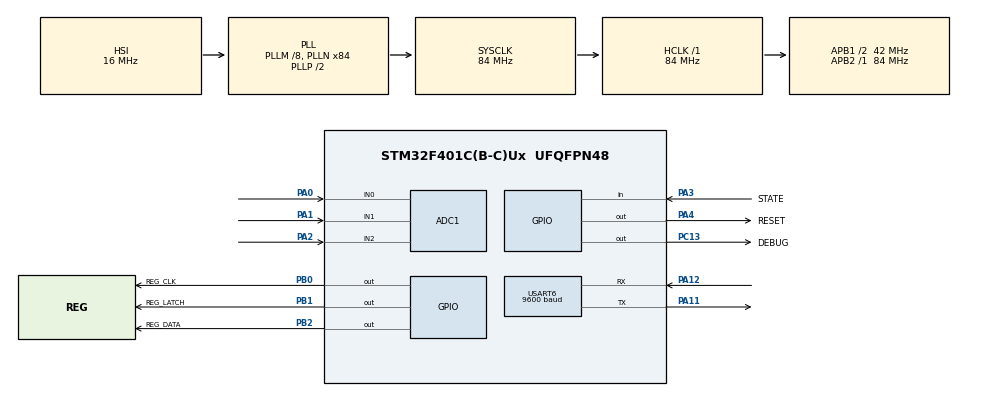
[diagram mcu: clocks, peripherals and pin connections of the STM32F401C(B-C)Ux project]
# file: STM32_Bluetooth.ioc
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ADC1.Channel-0\#ChannelRegularConversion=ADC_CHANNEL_0
ADC1.Channel-1\#ChannelRegularConversion=ADC_CHANNEL_1
ADC1.Channel-2\#ChannelRegularConversion=ADC_CHANNEL_2
ADC1.ContinuousConvMode=ENABLE
ADC1.NbrOfConversion=3
ADC1.NbrOfConversionFlag=1
ADC1.Rank-0\#ChannelRegularConversion=1
ADC1.Rank-1\#ChannelRegularConversion=2
ADC1.Rank-2\#ChannelRegularConversion=3
ADC1.SamplingTime-0\#ChannelRegularConversion=ADC_SAMPLETIME_56CYCLES
ADC1.SamplingTime-1\#ChannelRegularConversion=ADC_SAMPLETIME_56CYCLES
ADC1.SamplingTime-2\#ChannelRegularConversion=ADC_SAMPLETIME_56CYCLES
ADC1.master=1
Mcu.Family=STM32F4
Mcu.Name=STM32F401C(B-C)Ux
Mcu.Package=UFQFPN48
NVIC.PriorityGroup=NVIC_PRIORITYGROUP_4
NVIC.USART6_IRQn=true\:0\:0\:false\:false\:true\:true\:true\:true
PA0-WKUP.Signal=ADCx_IN0
PA1.Signal=ADCx_IN1
PA11.Mode=Asynchronous
PA11.Signal=USART6_TX
PA12.Mode=Asynchronous
PA12.Signal=USART6_RX
PA2.Signal=ADCx_IN2
PA3.GPIO_Label=STATE
PA3.GPIO_PuPd=GPIO_PULLDOWN
PA3.Signal=GPIO_Input
PA4.GPIO_Label=RESET
PA4.PinState=GPIO_PIN_SET
PA4.Signal=GPIO_Output
PB0.GPIO_Label=REG_CLK
PB0.GPIO_Speed=GPIO_SPEED_FREQ_VERY_HIGH
PB0.PinState=GPIO_PIN_RESET
PB0.Signal=GPIO_Output
PB1.GPIO_Label=REG_LATCH
PB1.GPIO_Speed=GPIO_SPEED_FREQ_VERY_HIGH
PB1.PinState=GPIO_PIN_RESET
PB1.Signal=GPIO_Output
PB2.GPIO_Label=REG_DATA
PB2.GPIO_Speed=GPIO_SPEED_FREQ_VERY_HIGH
PB2.PinState=GPIO_PIN_RESET
PB2.Signal=GPIO_Output
PC13-ANTI_TAMP.GPIO_Label=DEBUG
PC13-ANTI_TAMP.Signal=GPIO_Output
PH0\ -\ OSC_IN.Mode=HSE-External-Oscillator
PH0\ -\ OSC_IN.Signal=RCC_OSC_IN
PH1\ -\ OSC_OUT.Mode=HSE-External-Oscillator
PH1\ -\ OSC_OUT.Signal=RCC_OSC_OUT
ProjectManager.HeapSize=0x200
ProjectManager.StackSize=0x400
ProjectManager.TargetToolchain=STM32CubeIDE
RCC.48MHZClocksFreq_Value=42000000
RCC.AHBFreq_Value=84000000
RCC.APB1CLKDivider=RCC_HCLK_DIV2
RCC.APB1Freq_Value=42000000
RCC.APB1TimFreq_Value=84000000
RCC.APB2Freq_Value=84000000
RCC.APB2TimFreq_Value=84000000
RCC.CortexFreq_Value=84000000
RCC.HCLKFreq_Value=84000000
RCC.HSE_VALUE=25000000
RCC.HSI_VALUE=16000000
RCC.LSE_VALUE=32768
RCC.PLLM=8
RCC.PLLN=84
RCC.SYSCLKFreq_VALUE=84000000
RCC.SYSCLKSource=RCC_SYSCLKSOURCE_PLLCLK
RCC.VCOOutputFreq_Value=168000000
SH.ADCx_IN0.0=ADC1_IN0,IN0
SH.ADCx_IN1.0=ADC1_IN1,IN1
SH.ADCx_IN2.0=ADC1_IN2,IN2
USART6.BaudRate=9600
USART6.VirtualMode=VM_ASYNC
board=custom

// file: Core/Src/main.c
/* USER CODE BEGIN Header */
/**
  ******************************************************************************
  * @file           : main.c
  * @brief          : Main program body
  ******************************************************************************
  * @attention
  *
  * Copyright (c) 2024 STMicroelectronics.
  * All rights reserved.
  *
  * This software is licensed under terms that can be found in the LICENSE file
  * in the root directory of this software component.
  * If no LICENSE file comes with this software, it is provided AS-IS.
  *
  ******************************************************************************
  */
/* USER CODE END Header */
#include "main.h"

/* USER CODE BEGIN Includes */
#include "my_main.h"
/* USER CODE END Includes */

ADC_HandleTypeDef hadc1;

UART_HandleTypeDef huart6;

void SystemClock_Config(void);
static void MX_GPIO_Init(void);
static void MX_ADC1_Init(void);
static void MX_USART6_UART_Init(void);

int main(void)
{

  /* MCU Configuration--------------------------------------------------------*/

  /* Reset of all peripherals, Initializes the Flash interface and the Systick. */
  HAL_Init();

  /* Configure the system clock */
  SystemClock_Config();

  /* Initialize all configured peripherals */
  MX_GPIO_Init();
  MX_ADC1_Init();
  MX_USART6_UART_Init();

  /* Infinite loop */
  while (1)
  {

    /* USER CODE BEGIN 3 */
	  MAIN();
  }
  /* USER CODE END 3 */
}

void SystemClock_Config(void)
{
  RCC_OscInitTypeDef RCC_OscInitStruct = {0};
  RCC_ClkInitTypeDef RCC_ClkInitStruct = {0};

  /** Configure the main internal regulator output voltage
  */
  __HAL_RCC_PWR_CLK_ENABLE();
  __HAL_PWR_VOLTAGESCALING_CONFIG(PWR_REGULATOR_VOLTAGE_SCALE2);

  /** Initializes the RCC Oscillators according to the specified parameters
  * in the RCC_OscInitTypeDef structure.
  */
  RCC_OscInitStruct.OscillatorType = RCC_OSCILLATORTYPE_HSI;
  RCC_OscInitStruct.HSIState = RCC_HSI_ON;
  RCC_OscInitStruct.HSICalibrationValue = RCC_HSICALIBRATION_DEFAULT;
  RCC_OscInitStruct.PLL.PLLState = RCC_PLL_ON;
  RCC_OscInitStruct.PLL.PLLSource = RCC_PLLSOURCE_HSI;
  RCC_OscInitStruct.PLL.PLLM = 8;
  RCC_OscInitStruct.PLL.PLLN = 84;
  RCC_OscInitStruct.PLL.PLLP = RCC_PLLP_DIV2;
  RCC_OscInitStruct.PLL.PLLQ = 4;
  if (HAL_RCC_OscConfig(&RCC_OscInitStruct) != HAL_OK)
  {
    Error_Handler();
  }

  /** Initializes the CPU, AHB and APB buses clocks
  */
  RCC_ClkInitStruct.ClockType = RCC_CLOCKTYPE_HCLK|RCC_CLOCKTYPE_SYSCLK
                              |RCC_CLOCKTYPE_PCLK1|RCC_CLOCKTYPE_PCLK2;
  RCC_ClkInitStruct.SYSCLKSource = RCC_SYSCLKSOURCE_PLLCLK;
  RCC_ClkInitStruct.AHBCLKDivider = RCC_SYSCLK_DIV1;
  RCC_ClkInitStruct.APB1CLKDivider = RCC_HCLK_DIV2;
  RCC_ClkInitStruct.APB2CLKDivider = RCC_HCLK_DIV1;

  if (HAL_RCC_ClockConfig(&RCC_ClkInitStruct, FLASH_LATENCY_2) != HAL_OK)
  {
    Error_Handler();
  }
}

static void MX_ADC1_Init(void)
{

  ADC_ChannelConfTypeDef sConfig = {0};

  /** Configure the global features of the ADC (Clock, Resolution, Data Alignment and number of conversion)
  */
  hadc1.Instance = ADC1;
  hadc1.Init.ClockPrescaler = ADC_CLOCK_SYNC_PCLK_DIV4;
  hadc1.Init.Resolution = ADC_RESOLUTION_12B;
  hadc1.Init.ScanConvMode = ENABLE;
  hadc1.Init.ContinuousConvMode = ENABLE;
  hadc1.Init.DiscontinuousConvMode = DISABLE;
  hadc1.Init.ExternalTrigConvEdge = ADC_EXTERNALTRIGCONVEDGE_NONE;
  hadc1.Init.ExternalTrigConv = ADC_SOFTWARE_START;
  hadc1.Init.DataAlign = ADC_DATAALIGN_RIGHT;
  hadc1.Init.NbrOfConversion = 3;
  hadc1.Init.DMAContinuousRequests = DISABLE;
  hadc1.Init.EOCSelection = ADC_EOC_SINGLE_CONV;
  if (HAL_ADC_Init(&hadc1) != HAL_OK)
  {
    Error_Handler();
  }

  /** Configure for the selected ADC regular channel its corresponding rank in the sequencer and its sample time.
  */
  sConfig.Channel = ADC_CHANNEL_0;
  sConfig.Rank = 1;
  sConfig.SamplingTime = ADC_SAMPLETIME_56CYCLES;
  if (HAL_ADC_ConfigChannel(&hadc1, &sConfig) != HAL_OK)
  {
    Error_Handler();
  }

  /** Configure for the selected ADC regular channel its corresponding rank in the sequencer and its sample time.
  */
  sConfig.Channel = ADC_CHANNEL_1;
  sConfig.Rank = 2;
  if (HAL_ADC_ConfigChannel(&hadc1, &sConfig) != HAL_OK)
  {
    Error_Handler();
  }

  /** Configure for the selected ADC regular channel its corresponding rank in the sequencer and its sample time.
  */
  sConfig.Channel = ADC_CHANNEL_2;
  sConfig.Rank = 3;
  if (HAL_ADC_ConfigChannel(&hadc1, &sConfig) != HAL_OK)
  {
    Error_Handler();
  }

}

static void MX_USART6_UART_Init(void)
{

  huart6.Instance = USART6;
  huart6.Init.BaudRate = 9600;
  huart6.Init.WordLength = UART_WORDLENGTH_8B;
  huart6.Init.StopBits = UART_STOPBITS_1;
  huart6.Init.Parity = UART_PARITY_NONE;
  huart6.Init.Mode = UART_MODE_TX_RX;
  huart6.Init.HwFlowCtl = UART_HWCONTROL_NONE;
  huart6.Init.OverSampling = UART_OVERSAMPLING_16;
  if (HAL_UART_Init(&huart6) != HAL_OK)
  {
    Error_Handler();
  }

}

static void MX_GPIO_Init(void)
{
  GPIO_InitTypeDef GPIO_InitStruct = {0};

  /* GPIO Ports Clock Enable */
  __HAL_RCC_GPIOC_CLK_ENABLE();
  __HAL_RCC_GPIOH_CLK_ENABLE();
  __HAL_RCC_GPIOA_CLK_ENABLE();
  __HAL_RCC_GPIOB_CLK_ENABLE();

  /*Configure GPIO pin Output Level */
  HAL_GPIO_WritePin(DEBUG_GPIO_Port, DEBUG_Pin, GPIO_PIN_RESET);

  /*Configure GPIO pin Output Level */
  HAL_GPIO_WritePin(RESET_GPIO_Port, RESET_Pin, GPIO_PIN_SET);

  /*Configure GPIO pin Output Level */
  HAL_GPIO_WritePin(GPIOB, REG_CLK_Pin|REG_LATCH_Pin|REG_DATA_Pin, GPIO_PIN_RESET);

  /*Configure GPIO pin : DEBUG_Pin */
  GPIO_InitStruct.Pin = DEBUG_Pin;
  GPIO_InitStruct.Mode = GPIO_MODE_OUTPUT_PP;
  GPIO_InitStruct.Pull = GPIO_NOPULL;
  GPIO_InitStruct.Speed = GPIO_SPEED_FREQ_LOW;
  HAL_GPIO_Init(DEBUG_GPIO_Port, &GPIO_InitStruct);

  /*Configure GPIO pin : STATE_Pin */
  GPIO_InitStruct.Pin = STATE_Pin;
  GPIO_InitStruct.Mode = GPIO_MODE_INPUT;
  GPIO_InitStruct.Pull = GPIO_PULLDOWN;
  HAL_GPIO_Init(STATE_GPIO_Port, &GPIO_InitStruct);

  /*Configure GPIO pin : RESET_Pin */
  GPIO_InitStruct.Pin = RESET_Pin;
  GPIO_InitStruct.Mode = GPIO_MODE_OUTPUT_PP;
  GPIO_InitStruct.Pull = GPIO_NOPULL;
  GPIO_InitStruct.Speed = GPIO_SPEED_FREQ_LOW;
  HAL_GPIO_Init(RESET_GPIO_Port, &GPIO_InitStruct);

  /*Configure GPIO pins : REG_CLK_Pin REG_LATCH_Pin REG_DATA_Pin */
  GPIO_InitStruct.Pin = REG_CLK_Pin|REG_LATCH_Pin|REG_DATA_Pin;
  GPIO_InitStruct.Mode = GPIO_MODE_OUTPUT_PP;
  GPIO_InitStruct.Pull = GPIO_NOPULL;
  GPIO_InitStruct.Speed = GPIO_SPEED_FREQ_VERY_HIGH;
  HAL_GPIO_Init(GPIOB, &GPIO_InitStruct);

}

void Error_Handler(void)
{
  __disable_irq();
  while (1)
  {
  }
}
